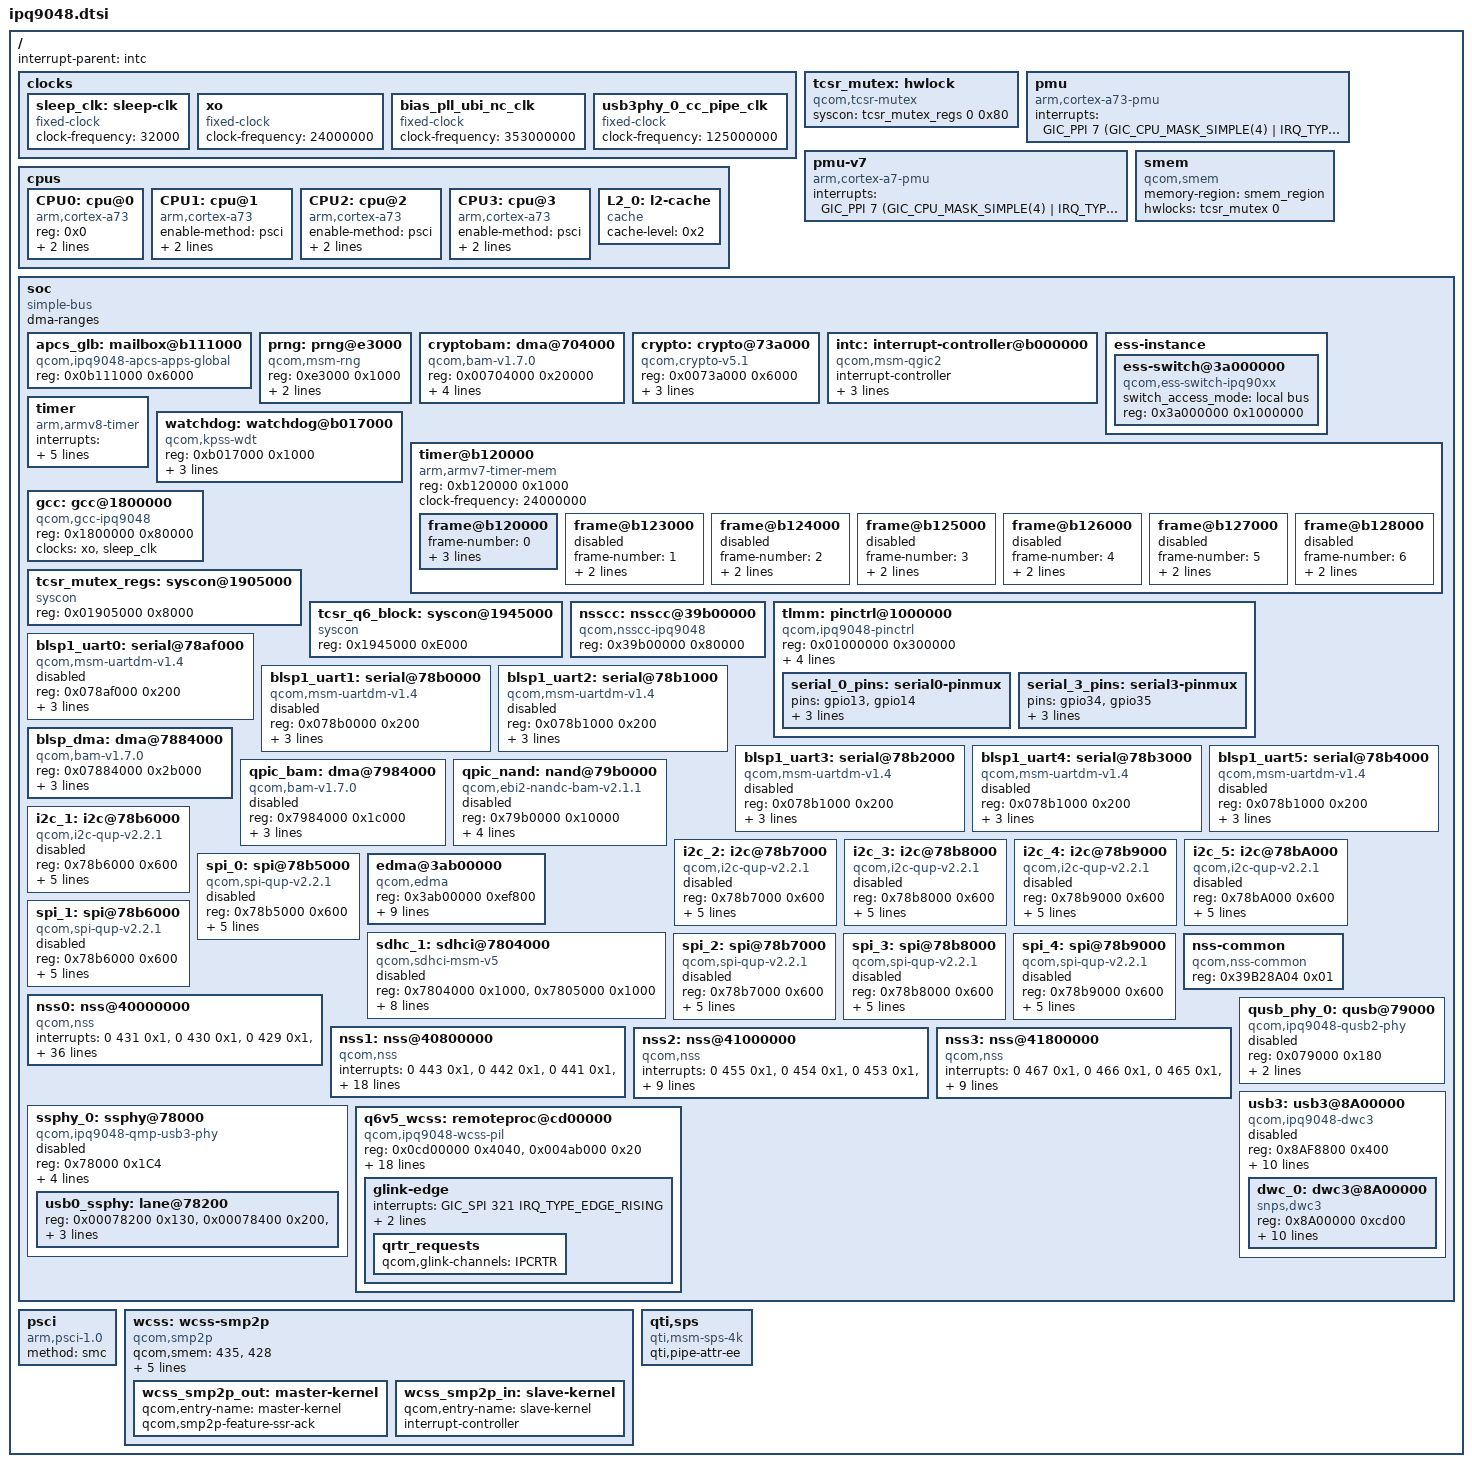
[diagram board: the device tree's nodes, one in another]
// SPDX-License-Identifier: (GPL-2.0+ OR BSD-3-Clause)
/*
 * IPQ9048 SoC device tree source
 *
 * Copyright (c) 2020-2021 The Linux Foundation. All rights reserved.
 */

#include <dt-bindings/interrupt-controller/arm-gic.h>
#include <dt-bindings/clock/qcom,gcc-ipq9048.h>
#include <dt-bindings/reset/qcom,gcc-ipq9048.h>
#include "ipq9048-memory.dtsi"
#include <dt-bindings/clock/qcom,nsscc-ipq9048.h>
#include <dt-bindings/reset/qcom,nsscc-ipq9048.h>

/ {
	#address-cells = <2>;
	#size-cells = <2>;
	interrupt-parent = <&intc>;

	clocks {
		sleep_clk: sleep-clk {
			compatible = "fixed-clock";
			clock-frequency = <32000>;
			#clock-cells = <0>;
		};

		xo: xo {
			compatible = "fixed-clock";
			clock-frequency = <24000000>;
			#clock-cells = <0>;
		};

		bias_pll_ubi_nc_clk {
			compatible = "fixed-clock";
			clock-frequency = <353000000>;
			#clock-cells = <0>;
		};

		usb3phy_0_cc_pipe_clk {
			compatible = "fixed-clock";
			clock-frequency = <125000000>;
			#clock-cells = <0>;
		};
	};

	cpus: cpus {
		#address-cells = <1>;
		#size-cells = <0>;

		CPU0: cpu@0 {
			device_type = "cpu";
			compatible = "arm,cortex-a73";
			reg = <0x0>;
			enable-method = "psci";
			next-level-cache = <&L2_0>;
		};

		CPU1: cpu@1 {
			device_type = "cpu";
			compatible = "arm,cortex-a73";
			enable-method = "psci";
			reg = <0x1>;
			next-level-cache = <&L2_0>;
		};

		CPU2: cpu@2 {
			device_type = "cpu";
			compatible = "arm,cortex-a73";
			enable-method = "psci";
			reg = <0x2>;
			next-level-cache = <&L2_0>;
		};

		CPU3: cpu@3 {
			device_type = "cpu";
			compatible = "arm,cortex-a73";
			enable-method = "psci";
			reg = <0x3>;
			next-level-cache = <&L2_0>;
		};

		L2_0: l2-cache {
			compatible = "cache";
			cache-level = <0x2>;
		};
	};

	tcsr_mutex: hwlock {
		compatible = "qcom,tcsr-mutex";
		syscon = <&tcsr_mutex_regs 0 0x80>;
		#hwlock-cells = <1>;
	};

	pmu {
		compatible = "arm,cortex-a73-pmu";
		interrupts = <GIC_PPI 7 (GIC_CPU_MASK_SIMPLE(4) | IRQ_TYPE_LEVEL_HIGH)>;
	};

	pmu-v7 {
		compatible = "arm,cortex-a7-pmu";
		interrupts = <GIC_PPI 7 (GIC_CPU_MASK_SIMPLE(4) | IRQ_TYPE_LEVEL_HIGH)>;
	};

	smem {
		compatible = "qcom,smem";
		memory-region = <&smem_region>;
		hwlocks = <&tcsr_mutex 0>;
	};

	soc: soc {
		#address-cells = <1>;
		#size-cells = <1>;
		ranges = <0 0 0 0xffffffff>;
		dma-ranges;
		compatible = "simple-bus";

		apcs_glb: mailbox@b111000 {
			compatible = "qcom,ipq9048-apcs-apps-global";
			reg = <0x0b111000 0x6000>;

			#mbox-cells = <1>;
		};

		prng: prng@e3000 {
			compatible = "qcom,msm-rng";
			reg = <0xe3000 0x1000>;
			clocks = <&gcc GCC_PRNG_AHB_CLK>;
			clock-names = "km_clk_src";
			qcom,no-qrng-config;
		};

		cryptobam: dma@704000 {
			compatible = "qcom,bam-v1.7.0";
			reg = <0x00704000 0x20000>;
			interrupts = <GIC_SPI 207 IRQ_TYPE_LEVEL_HIGH>;
			clocks = <&gcc GCC_CRYPTO_AHB_CLK>;
			clock-names = "bam_clk";
			#dma-cells = <1>;
			qcom,ee = <1>;
			qcom,controlled-remotely = <1>;
		};

		crypto: crypto@73a000 {
			compatible = "qcom,crypto-v5.1";
			reg = <0x0073a000 0x6000>;
			clocks = <&gcc GCC_CRYPTO_AHB_CLK>,
				<&gcc GCC_CRYPTO_AXI_CLK>,
				<&gcc GCC_CRYPTO_CLK>;
			clock-names = "iface", "bus", "core";
			dmas = <&cryptobam 2>, <&cryptobam 3>;
			dma-names = "rx", "tx";
		};

		intc: interrupt-controller@b000000 {
			compatible = "qcom,msm-qgic2";
			interrupt-controller;
			#interrupt-cells = <0x3>;
			reg = <0x0b000000 0x1000>,  /*GICD*/
				<0x0b002000 0x1000>,  /*GICC*/
				<0x0b001000 0x1000>,  /*GICH*/
				<0x0b004000 0x1000>;  /*GICV*/
			interrupts = <GIC_PPI 9 IRQ_TYPE_LEVEL_HIGH>;
		};

		ess-instance {
			ess-switch@3a000000 {
				compatible = "qcom,ess-switch-ipq90xx";
				switch_access_mode = "local bus";
				reg = <0x3a000000 0x1000000>;
			};
		};
		timer {
			compatible = "arm,armv8-timer";
			interrupts = <GIC_PPI 2 (GIC_CPU_MASK_SIMPLE(4) | IRQ_TYPE_LEVEL_LOW)>,
				<GIC_PPI 3 (GIC_CPU_MASK_SIMPLE(4) | IRQ_TYPE_LEVEL_LOW)>,
				<GIC_PPI 4 (GIC_CPU_MASK_SIMPLE(4) | IRQ_TYPE_LEVEL_LOW)>,
				<GIC_PPI 1 (GIC_CPU_MASK_SIMPLE(4) | IRQ_TYPE_LEVEL_LOW)>;
			clock-frequency = <24000000>;
		};

		watchdog: watchdog@b017000 {
			compatible = "qcom,kpss-wdt";
			reg = <0xb017000 0x1000>;
			interrupts = <GIC_SPI 3 IRQ_TYPE_EDGE_RISING>;
			clocks = <&sleep_clk>;
			max-timeout-sec = <32>;
		};

		timer@b120000 {
			#address-cells = <1>;
			#size-cells = <1>;
			ranges;
			compatible = "arm,armv7-timer-mem";
			reg = <0xb120000 0x1000>;
			clock-frequency = <24000000>;

			frame@b120000 {
				frame-number = <0>;
				interrupts = <GIC_SPI 8 IRQ_TYPE_LEVEL_HIGH>,
					     <GIC_SPI 7 IRQ_TYPE_LEVEL_HIGH>;
				reg = <0xb121000 0x1000>,
				      <0xb122000 0x1000>;
			};

			frame@b123000 {
				frame-number = <1>;
				interrupts = <GIC_SPI 9 IRQ_TYPE_LEVEL_HIGH>;
				reg = <0xb123000 0x1000>;
				status = "disabled";
			};

			frame@b124000 {
				frame-number = <2>;
				interrupts = <GIC_SPI 10 IRQ_TYPE_LEVEL_HIGH>;
				reg = <0xb124000 0x1000>;
				status = "disabled";
			};

			frame@b125000 {
				frame-number = <3>;
				interrupts = <GIC_SPI 11 IRQ_TYPE_LEVEL_HIGH>;
				reg = <0xb125000 0x1000>;
				status = "disabled";
			};

			frame@b126000 {
				frame-number = <4>;
				interrupts = <GIC_SPI 12 IRQ_TYPE_LEVEL_HIGH>;
				reg = <0xb126000 0x1000>;
				status = "disabled";
			};

			frame@b127000 {
				frame-number = <5>;
				interrupts = <GIC_SPI 13 IRQ_TYPE_LEVEL_HIGH>;
				reg = <0xb127000 0x1000>;
				status = "disabled";
			};

			frame@b128000 {
				frame-number = <6>;
				interrupts = <GIC_SPI 14 IRQ_TYPE_LEVEL_HIGH>;
				reg = <0xb128000 0x1000>;
				status = "disabled";
			};
		};

		gcc: gcc@1800000 {
			compatible = "qcom,gcc-ipq9048";
			reg = <0x1800000 0x80000>;
			clocks = <&xo>, <&sleep_clk>;
			clock-names = "xo", "sleep_clk";
			#clock-cells = <0x1>;
			#reset-cells = <0x1>;
		};

		tcsr_mutex_regs: syscon@1905000 {
			compatible = "syscon";
			reg = <0x01905000 0x8000>;
		};

		tcsr_q6_block: syscon@1945000 {
			compatible = "syscon";
			reg = <0x1945000 0xE000>;
		};

		nsscc: nsscc@39b00000 {
			compatible = "qcom,nsscc-ipq9048";
			reg = <0x39b00000 0x80000>;
			#clock-cells = <0x1>;
			#reset-cells = <0x1>;
		};

		tlmm: pinctrl@1000000 {
			compatible = "qcom,ipq9048-pinctrl";
			reg = <0x01000000 0x300000>;
			interrupts = <GIC_SPI 208 IRQ_TYPE_LEVEL_HIGH>;
			gpio-controller;
			#gpio-cells = <2>;
			gpio-ranges = <&tlmm 0 0 65>;
			interrupt-controller;
			#interrupt-cells = <2>;

			serial_0_pins: serial0-pinmux {
				pins = "gpio13", "gpio14";
				function = "blsp0_uart";
				drive-strength = <8>;
				bias-pull-down;
			};

			serial_3_pins: serial3-pinmux {
				pins = "gpio34", "gpio35";
				function = "blsp2_uart";
				drive-strength = <8>;
				bias-pull-down;
			};
		};

		blsp1_uart0: serial@78af000 {
			compatible = "qcom,msm-uartdm-v1.4", "qcom,msm-uartdm";
			reg = <0x078af000 0x200>;
			interrupts = <GIC_SPI 107 IRQ_TYPE_LEVEL_HIGH>;
			clocks = <&gcc GCC_BLSP1_UART1_APPS_CLK>,
				 <&gcc GCC_BLSP1_AHB_CLK>;
			clock-names = "core", "iface";
			status = "disabled";
		};

		blsp1_uart1: serial@78b0000 {
			compatible = "qcom,msm-uartdm-v1.4", "qcom,msm-uartdm";
			reg = <0x078b0000 0x200>;
			interrupts = <GIC_SPI 108 IRQ_TYPE_LEVEL_HIGH>;
			clocks = <&gcc GCC_BLSP1_UART2_APPS_CLK>,
				 <&gcc GCC_BLSP1_AHB_CLK>;
			clock-names = "core", "iface";
			status = "disabled";
		};

		blsp1_uart2: serial@78b1000 {
			compatible = "qcom,msm-uartdm-v1.4", "qcom,msm-uartdm";
			reg = <0x078b1000 0x200>;
			interrupts = <GIC_SPI 306 IRQ_TYPE_LEVEL_HIGH>;
			clocks = <&gcc GCC_BLSP1_UART3_APPS_CLK>,
				 <&gcc GCC_BLSP1_AHB_CLK>;
			clock-names = "core", "iface";
			status = "disabled";
		};

		blsp1_uart3: serial@78b2000 {
			compatible = "qcom,msm-uartdm-v1.4", "qcom,msm-uartdm";
			reg = <0x078b1000 0x200>;
			interrupts = <GIC_SPI 307 IRQ_TYPE_LEVEL_HIGH>;
			clocks = <&gcc GCC_BLSP1_UART4_APPS_CLK>,
				 <&gcc GCC_BLSP1_AHB_CLK>;
			clock-names = "core", "iface";
			status = "disabled";
		};

		blsp1_uart4: serial@78b3000 {
			compatible = "qcom,msm-uartdm-v1.4", "qcom,msm-uartdm";
			reg = <0x078b1000 0x200>;
			interrupts = <GIC_SPI 308 IRQ_TYPE_LEVEL_HIGH>;
			clocks = <&gcc GCC_BLSP1_UART5_APPS_CLK>,
				 <&gcc GCC_BLSP1_AHB_CLK>;
			clock-names = "core", "iface";
			status = "disabled";
		};

		blsp1_uart5: serial@78b4000 {
			compatible = "qcom,msm-uartdm-v1.4", "qcom,msm-uartdm";
			reg = <0x078b1000 0x200>;
			interrupts = <GIC_SPI 309 IRQ_TYPE_LEVEL_HIGH>;
			clocks = <&gcc GCC_BLSP1_UART6_APPS_CLK>,
				 <&gcc GCC_BLSP1_AHB_CLK>;
			clock-names = "core", "iface";
			status = "disabled";
		};

		blsp_dma: dma@7884000 {
			compatible = "qcom,bam-v1.7.0";
			reg = <0x07884000 0x2b000>;
			interrupts = <GIC_SPI 238 IRQ_TYPE_LEVEL_HIGH>;
			clocks = <&gcc GCC_BLSP1_AHB_CLK>;
			clock-names = "bam_clk";
			#dma-cells = <1>;
			qcom,ee = <0>;
		};

		qpic_bam: dma@7984000 {
			compatible = "qcom,bam-v1.7.0";
			reg = <0x7984000 0x1c000>;
			interrupts = <GIC_SPI 146 IRQ_TYPE_LEVEL_HIGH>;
			clocks = <&gcc GCC_QPIC_AHB_CLK>;
			clock-names = "bam_clk";
			#dma-cells = <1>;
			qcom,ee = <0>;
			status = "disabled";
		};

		qpic_nand: nand@79b0000 {
			compatible = "qcom,ebi2-nandc-bam-v2.1.1";
			reg = <0x79b0000 0x10000>;
			#address-cells = <1>;
			#size-cells = <0>;
			clocks = <&gcc GCC_QPIC_CLK>,
			<&gcc GCC_QPIC_AHB_CLK>,
			<&gcc GCC_QPIC_IO_MACRO_CLK>;
			clock-names = "core", "aon", "io_macro";

			dmas = <&qpic_bam 0>,
				<&qpic_bam 1>,
				<&qpic_bam 2>;
			dma-names = "tx", "rx", "cmd";
			status = "disabled";
		};

                i2c_1: i2c@78b6000 {
                        compatible = "qcom,i2c-qup-v2.2.1";
                        #address-cells = <1>;
                        #size-cells = <0>;
                        reg = <0x78b6000 0x600>;
                        interrupts = <GIC_SPI 96 IRQ_TYPE_LEVEL_HIGH>;
                        clocks = <&gcc GCC_BLSP1_AHB_CLK>,
                                <&gcc GCC_BLSP1_QUP2_I2C_APPS_CLK>;                                                                                            clock-names = "iface", "core";
                        clock-frequency  = <400000>;
                        dmas = <&blsp_dma 15>, <&blsp_dma 14>;
                        dma-names = "rx", "tx";
                        status = "disabled";
                };

                i2c_2: i2c@78b7000 {
                        compatible = "qcom,i2c-qup-v2.2.1";
                        #address-cells = <1>;
                        #size-cells = <0>;
                        reg = <0x78b7000 0x600>;
                        interrupts = <GIC_SPI 97 IRQ_TYPE_LEVEL_HIGH>;
                        clocks = <&gcc GCC_BLSP1_AHB_CLK>,
                                <&gcc GCC_BLSP1_QUP3_I2C_APPS_CLK>;
                        clock-names = "iface", "core";
                        clock-frequency  = <400000>;
                        dmas = <&blsp_dma 17>, <&blsp_dma 16>;
                        dma-names = "rx", "tx";
                        status = "disabled";
                };

                i2c_3: i2c@78b8000 {
                        compatible = "qcom,i2c-qup-v2.2.1";
                        #address-cells = <1>;
                        #size-cells = <0>;
                        reg = <0x78b8000 0x600>;
                        interrupts = <GIC_SPI 98 IRQ_TYPE_LEVEL_HIGH>;
                        clocks = <&gcc GCC_BLSP1_AHB_CLK>,
                                <&gcc GCC_BLSP1_QUP4_I2C_APPS_CLK>;
                        clock-names = "iface", "core";
                        clock-frequency  = <400000>;
                        dmas = <&blsp_dma 19>, <&blsp_dma 18>;
                        dma-names = "rx", "tx";
                        status = "disabled";
                };

                i2c_4: i2c@78b9000 {
                        compatible = "qcom,i2c-qup-v2.2.1";
                        #address-cells = <1>;
                        #size-cells = <0>;
                        reg = <0x78b9000 0x600>;
                        interrupts = <GIC_SPI 299 IRQ_TYPE_LEVEL_HIGH>;
                        clocks = <&gcc GCC_BLSP1_AHB_CLK>,
                                <&gcc GCC_BLSP1_QUP5_I2C_APPS_CLK>;
                        clock-names = "iface", "core";
                        clock-frequency  = <400000>;
                        dmas = <&blsp_dma 21>, <&blsp_dma 20>;
                        dma-names = "rx", "tx";
                        status = "disabled";
                };

                i2c_5: i2c@78bA000 {
                        compatible = "qcom,i2c-qup-v2.2.1";
                        #address-cells = <1>;
                        #size-cells = <0>;
                        reg = <0x78bA000 0x600>;
                        interrupts = <GIC_SPI 300 IRQ_TYPE_LEVEL_HIGH>;
                        clocks = <&gcc GCC_BLSP1_AHB_CLK>,
                                <&gcc GCC_BLSP1_QUP6_I2C_APPS_CLK>;
                        clock-names = "iface", "core";
                        clock-frequency  = <400000>;
                        dmas = <&blsp_dma 23>, <&blsp_dma 22>;
                        dma-names = "rx", "tx";
                        status = "disabled";
                };

		spi_0: spi@78b5000 {
			compatible = "qcom,spi-qup-v2.2.1";
			#address-cells = <1>;
			#size-cells = <0>;
			reg = <0x78b5000 0x600>;
			interrupts = <GIC_SPI 95 IRQ_TYPE_LEVEL_HIGH>;
			spi-max-frequency = <50000000>;
			clocks = <&gcc GCC_BLSP1_QUP1_SPI_APPS_CLK>,
				<&gcc GCC_BLSP1_AHB_CLK>;
			clock-names = "core", "iface";
			dmas = <&blsp_dma 12>, <&blsp_dma 13>;
			dma-names = "tx", "rx";
			status = "disabled";
		};

		edma@3ab00000 {
			compatible = "qcom,edma";
			reg = <0x3ab00000 0xef800>;
			reg-names = "edma-reg-base";
			qcom,txdesc-ring-start = <31>;
			qcom,txdesc-rings = <0>;
			qcom,txcmpl-ring-start = <31>;
			qcom,txcmpl-rings = <0>;
			qcom,rxfill-ring-start = <7>;
			qcom,rxfill-rings = <0>;
			qcom,rxdesc-ring-start = <23>;
			qcom,rxdesc-rings = <0>;
			interrupts = <0 262 4>,
				   <0 362 4>,
				   <0 354 4>,
				   <0 261 4>;
		};

		sdhc_1: sdhci@7804000 {
			compatible = "qcom,sdhci-msm-v5";
			reg = <0x7804000 0x1000>, <0x7805000 0x1000>;
			reg-names = "hc_mem", "cmdq_mem";

			interrupts = <GIC_SPI 123 IRQ_TYPE_LEVEL_HIGH>,
					<GIC_SPI 138 IRQ_TYPE_LEVEL_HIGH>;
			interrupt-names = "hc_irq", "pwr_irq";

			clocks = <&xo>,
				<&gcc GCC_SDCC1_AHB_CLK>,
				<&gcc GCC_SDCC1_APPS_CLK>;
			clock-names = "xo", "iface", "core";
			max-frequency = <48000000>;
			mmc-ddr-3_3v;
			bus-width = <8>;
			non-removable;
			status = "disabled";
		};

		spi_1: spi@78b6000 {
			compatible = "qcom,spi-qup-v2.2.1";
			#address-cells = <1>;
			#size-cells = <0>;
			reg = <0x78b6000 0x600>;
			interrupts = <GIC_SPI 96 IRQ_TYPE_LEVEL_HIGH>;
			spi-max-frequency = <50000000>;
			clocks = <&gcc GCC_BLSP1_QUP2_SPI_APPS_CLK>,
				<&gcc GCC_BLSP1_AHB_CLK>;
			clock-names = "core", "iface";
			dmas = <&blsp_dma 14>, <&blsp_dma 15>;
			dma-names = "tx", "rx";
			status = "disabled";
		};

		spi_2: spi@78b7000 {
			compatible = "qcom,spi-qup-v2.2.1";
			#address-cells = <1>;
			#size-cells = <0>;
			reg = <0x78b7000 0x600>;
			interrupts = <GIC_SPI 97 IRQ_TYPE_LEVEL_HIGH>;
			spi-max-frequency = <50000000>;
			clocks = <&gcc GCC_BLSP1_QUP3_SPI_APPS_CLK>,
				<&gcc GCC_BLSP1_AHB_CLK>;
			clock-names = "core", "iface";
			dmas = <&blsp_dma 16>, <&blsp_dma 17>;
			dma-names = "tx", "rx";
			status = "disabled";
		};

		spi_3: spi@78b8000 {
			compatible = "qcom,spi-qup-v2.2.1";
			#address-cells = <1>;
			#size-cells = <0>;
			reg = <0x78b8000 0x600>;
			interrupts = <GIC_SPI 98 IRQ_TYPE_LEVEL_HIGH>;
			spi-max-frequency = <50000000>;
			clocks = <&gcc GCC_BLSP1_QUP4_SPI_APPS_CLK>,
				<&gcc GCC_BLSP1_AHB_CLK>;
			clock-names = "core", "iface";
			dmas = <&blsp_dma 18>, <&blsp_dma 19>;
			dma-names = "tx", "rx";
			status = "disabled";
		};

		spi_4: spi@78b9000 {
			compatible = "qcom,spi-qup-v2.2.1";
			#address-cells = <1>;
			#size-cells = <0>;
			reg = <0x78b9000 0x600>;
			interrupts = <GIC_SPI 299 IRQ_TYPE_LEVEL_HIGH>;
			spi-max-frequency = <50000000>;
			clocks = <&gcc GCC_BLSP1_QUP5_SPI_APPS_CLK>,
				<&gcc GCC_BLSP1_AHB_CLK>;
			clock-names = "core", "iface";
			dmas = <&blsp_dma 20>, <&blsp_dma 21>;
			dma-names = "tx", "rx";
			status = "disabled";
		};

		nss-common {
			compatible = "qcom,nss-common";
			reg = <0x39B28A04 0x01>;
			reg-names = "nss-misc-reset";
		};

		nss0: nss@40000000 {
			compatible = "qcom,nss";
			interrupts = <0 431 0x1>, <0 430 0x1>, <0 429 0x1>,
				     <0 428 0x1>, <0 427 0x1>, <0 426 0x1>,
				     <0 425 0x1>, <0 424 0x1>, <0 423 0x1>,
				     <0 422 0x1>;
			reg = <0x38F00000 0x100>, <0x38200000 0xC000>,
			      <0xB11A000 0x1000>;
			reg-names = "nphys", "vphys", "qgic-phys";
			qcom,id = <0>;
			qcom,num-queue = <4>;
			qcom,num-irq = <10>;
			qcom,num-pri = <4>;
			qcom,load-addr = <0x40000000>;
			qcom,low-frequency = <1500000000>;
			qcom,mid-frequency = <1500000000>;
			qcom,max-frequency = <1700000000>;
			qcom,bridge-enabled;
			qcom,ipv4-enabled;
			qcom,ipv4-reasm-enabled;
			qcom,ipv6-enabled;
			qcom,ipv6-reasm-enabled;
			qcom,wlanredirect-enabled;
			qcom,tun6rd-enabled;
			qcom,l2tpv2-enabled;
			qcom,gre-enabled;
			qcom,gre-redir-enabled;
			qcom,gre-redir-mark-enabled;
			qcom,map-t-enabled;
			qcom,portid-enabled;
			qcom,ppe-enabled;
			qcom,pppoe-enabled;
			qcom,pptp-enabled;
			qcom,tunipip6-enabled;
			qcom,shaping-enabled;
			qcom,wlan-dataplane-offload-enabled;
			qcom,vlan-enabled;
			qcom,igs-enabled;
			qcom,vxlan-enabled;
			qcom,match-enabled;
			qcom,mirror-enabled;
		};

		nss1: nss@40800000 {
			compatible = "qcom,nss";
			interrupts = <0 443 0x1>, <0 442 0x1>, <0 441 0x1>,
				     <0 440 0x1>, <0 439 0x1>, <0 438 0x1>,
				     <0 437 0x1>, <0 436 0x1>, <0 435 0x1>,
				     <0 434 0x1>;
			reg = <0x38F01000 0x100>, <0x3820C000 0xC000>,
				<0xB11A000 0x1000>;
			reg-names = "nphys", "vphys", "qgic-phys";
			qcom,id = <1>;
			qcom,num-queue = <4>;
			qcom,num-irq = <10>;
			qcom,num-pri = <4>;
			qcom,load-addr = <0x40800000>;
			qcom,capwap-enabled;
			qcom,dtls-enabled;
			qcom,tls-enabled;
			qcom,crypto-enabled;
			qcom,ipsec-enabled;
			qcom,qvpn-enabled;
			qcom,pvxlan-enabled;
			qcom,clmap-enabled;
			qcom,rmnet_rx-enabled;
		};

		nss2: nss@41000000 {
			compatible = "qcom,nss";
			interrupts = <0 455 0x1>, <0 454 0x1>, <0 453 0x1>,
				     <0 452 0x1>, <0 451 0x1>, <0 450 0x1>,
				     <0 449 0x1>, <0 448 0x1>, <0 447 0x1>,
				     <0 446 0x1>;
			reg = <0x38F02000 0x100>, <0x38218000 0xC000>,
				<0xB11A000 0x1000>;
			reg-names = "nphys", "vphys", "qgic-phys";
			qcom,id = <2>;
			qcom,num-queue = <4>;
			qcom,num-irq = <10>;
			qcom,num-pri = <4>;
			qcom,load-addr = <0x41000000>;
		};

		nss3: nss@41800000 {
			compatible = "qcom,nss";
			interrupts = <0 467 0x1>, <0 466 0x1>, <0 465 0x1>,
				     <0 464 0x1>, <0 463 0x1>, <0 462 0x1>,
				     <0 461 0x1>, <0 460 0x1>, <0 459 0x1>,
				     <0 458 0x1>;
			reg = <0x38F03000 0x100>, <0x38224000 0xC000>,
				<0xB11A000 0x1000>;
			reg-names = "nphys", "vphys", "qgic-phys";
			qcom,id = <3>;
			qcom,num-queue = <4>;
			qcom,num-irq = <10>;
			qcom,num-pri = <4>;
			qcom,load-addr = <0x41800000>;
		};

		ssphy_0: ssphy@78000 {
			compatible = "qcom,ipq9048-qmp-usb3-phy";
			reg = <0x78000 0x1C4>;
			#clock-cells = <1>;
			#address-cells = <1>;
			#size-cells = <1>;
			ranges;

			clocks = <&gcc GCC_USB0_AUX_CLK>,
				 <&gcc GCC_USB0_PHY_CFG_AHB_CLK>;
			clock-names = "aux", "cfg_ahb";

			resets =  <&gcc GCC_USB0_PHY_BCR>,
				 <&gcc GCC_USB3PHY_0_PHY_BCR>;
			reset-names = "phy","common";
			status = "disabled";

			usb0_ssphy: lane@78200 {
				reg = <0x00078200 0x130>,	/* Tx */
				      <0x00078400 0x200>,	/* Rx */
				      <0x00078800 0x1F8>,	/* PCS  */
				      <0x00078600 0x044>;	/* PCS misc */
				#phy-cells = <0>;
				clocks = <&gcc GCC_USB0_PIPE_CLK>;
				clock-names = "pipe0";
				clock-output-names = "gcc_usb0_pipe_clk_src";
			};
		};

		qusb_phy_0: qusb@79000 {
		    compatible = "qcom,ipq9048-qusb2-phy";
		    reg = <0x079000 0x180>;
		    #phy-cells = <0>;

		    clocks = <&gcc GCC_USB0_PHY_CFG_AHB_CLK>,
			     <&xo>;
		    clock-names = "cfg_ahb", "ref";

		    resets = <&gcc GCC_QUSB2_0_PHY_BCR>;
		    status = "disabled";
		};

		usb3: usb3@8A00000 {
			compatible = "qcom,ipq9048-dwc3", "qcom,dwc3";
			reg = <0x8AF8800 0x400>;
			#address-cells = <1>;
			#size-cells = <1>;
			ranges;

			clocks = <&gcc GCC_ANOC_USB_AXI_CLK>,
				<&gcc GCC_USB0_MASTER_CLK>,
				<&gcc GCC_USB0_SLEEP_CLK>,
				<&gcc GCC_USB0_MOCK_UTMI_CLK>;
			clock-names = "sys_noc_axi",
				"master",
				"sleep",
				"mock_utmi";

			assigned-clocks = <&gcc GCC_ANOC_USB_AXI_CLK>,
					  <&gcc GCC_USB0_MASTER_CLK>,
					  <&gcc GCC_USB0_MOCK_UTMI_CLK>;
			assigned-clock-rates = <133330000>,
					       <133330000>,
					       <20000000>;

			resets = <&gcc GCC_USB_BCR>;
			status = "disabled";

			dwc_0: dwc3@8A00000 {
				compatible = "snps,dwc3";
				reg = <0x8A00000 0xcd00>;
				interrupts = <GIC_SPI 140 IRQ_TYPE_LEVEL_HIGH>;
				phys = <&qusb_phy_0>, <&usb0_ssphy>;
				phy-names = "usb2-phy", "usb3-phy";
				tx-fifo-resize;
				snps,dis_ep_cache_eviction;
				snps,is-utmi-l1-suspend;
				snps,hird-threshold = /bits/ 8 <0x0>;
				snps,dis_u2_susphy_quirk;
				snps,dis_u3_susphy_quirk;
				snps,quirk-ref-clock-period = <0x32>;
				dr_mode = "host";
			};
		};

		q6v5_wcss: remoteproc@cd00000 {
			compatible = "qcom,ipq9048-wcss-pil";
			reg = <0x0cd00000 0x4040>,
				<0x004ab000 0x20>;
			reg-names = "qdsp6",
				    "rmb";
			interrupts-extended = <&intc GIC_SPI 291 IRQ_TYPE_EDGE_RISING>,
					      <&wcss_smp2p_in 0 0>,
					      <&wcss_smp2p_in 1 0>,
					      <&wcss_smp2p_in 2 0>,
					      <&wcss_smp2p_in 3 0>;
			interrupt-names = "wdog",
					  "fatal",
					  "ready",
					  "handover",
					  "stop-ack";

			resets = <&gcc GCC_WCSSAON_RESET>,
				 <&gcc GCC_WCSS_BCR>,
				 <&gcc GCC_WCSS_Q6_BCR>;

			reset-names = "wcss_aon_reset",
				      "wcss_reset",
				      "wcss_q6_reset";

                        clocks = <&gcc GCC_WCSS_AHB_S_CLK>,
				 <&gcc GCC_WCSS_ECAHB_CLK>,
				 <&gcc GCC_WCSS_ACMT_CLK>,
				 <&gcc GCC_WCSS_AXI_M_CLK>,
				 <&gcc GCC_Q6_AXIM_CLK>,
				 <&gcc GCC_Q6_AXIM2_CLK>,
				 <&gcc GCC_Q6_AHB_CLK>,
				 <&gcc GCC_Q6_AHB_S_CLK>;
                        clock-names = "gcc_wcss_ahb_s_clk",
				      "gcc_wcss_ecahb_clk",
				      "gcc_wcss_acmt_clk",
				      "gcc_wcss_axi_m_clk",
				      "gcc_q6_axim_clk",
				      "gcc_q6_axim2_clk",
				      "gcc_q6_ahb_clk",
				      "gcc_q6_ahb_s_clk";

			qcom,halt-regs = <&tcsr_q6_block 0xa000 0xd000 0x0>;

			qcom,smem-states = <&wcss_smp2p_out 0>,
					   <&wcss_smp2p_out 1>;
			qcom,smem-state-names = "shutdown",
						"stop";

			memory-region = <&q6_region>;

			glink-edge {
				interrupts = <GIC_SPI 321 IRQ_TYPE_EDGE_RISING>;
				qcom,remote-pid = <1>;
				mboxes = <&apcs_glb 8>;

				qrtr_requests {
					qcom,glink-channels = "IPCRTR";
				};
			};
		};

	};

	psci {
		compatible = "arm,psci-1.0";
		method = "smc";
	};

	wcss: wcss-smp2p {
		compatible = "qcom,smp2p";
		qcom,smem = <435>, <428>;

		interrupt-parent = <&intc>;
		interrupts = <GIC_SPI 322 IRQ_TYPE_EDGE_RISING>;

		mboxes = <&apcs_glb 9>;

		qcom,local-pid = <0>;
		qcom,remote-pid = <1>;

		wcss_smp2p_out: master-kernel {
			qcom,entry-name = "master-kernel";
			qcom,smp2p-feature-ssr-ack;
			#qcom,smem-state-cells = <1>;
		};

		wcss_smp2p_in: slave-kernel {
			qcom,entry-name = "slave-kernel";
			interrupt-controller;
			#interrupt-cells = <2>;
		};
	};

	qti,sps {
		compatible = "qti,msm-sps-4k";
		qti,pipe-attr-ee;
	};
};

#include "ipq9048-coresight.dtsi"
